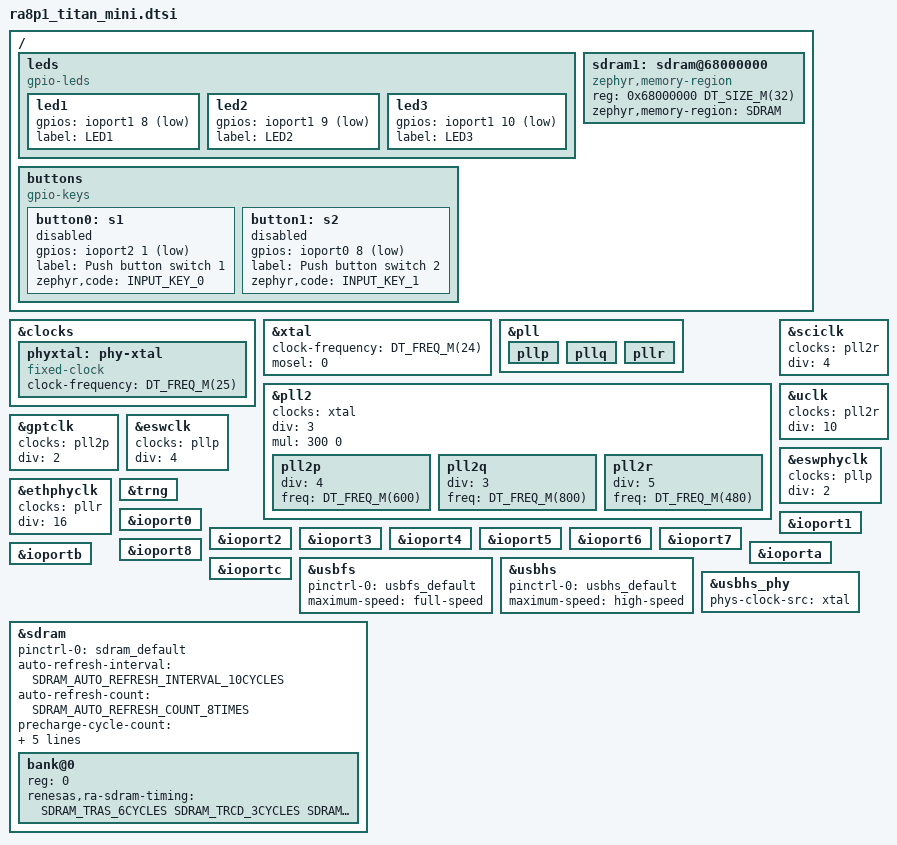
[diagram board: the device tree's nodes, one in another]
/*
 * SPDX-FileCopyrightText: Copyright The Zephyr Project Contributors
 * SPDX-License-Identifier: Apache-2.0
 */

#include <zephyr/dt-bindings/gpio/gpio.h>
#include <zephyr/dt-bindings/input/input-event-codes.h>
#include "ra8p1_titan_mini-pinctrl.dtsi"
#include <zephyr/dt-bindings/memory-attr/memory-attr-arm.h>
#include <zephyr/dt-bindings/memory-controller/renesas,ra-sdram.h>

/ {
	leds {
		compatible = "gpio-leds";

		led1: led1 {
			gpios = <&ioport1 8 GPIO_ACTIVE_LOW>;
			label = "LED1";
		};

		led2: led2 {
			gpios = <&ioport1 9 GPIO_ACTIVE_LOW>;
			label = "LED2";
		};

		led3: led3 {
			gpios = <&ioport1 10 GPIO_ACTIVE_LOW>;
			label = "LED3";
		};
	};

	buttons {
		compatible = "gpio-keys";

		button0: s1 {
			gpios = <&ioport2 1 GPIO_ACTIVE_LOW>;
			label = "Push button switch 1";
			zephyr,code = <INPUT_KEY_0>;
			status = "disabled";
		};

		button1: s2 {
			gpios = <&ioport0 8 (GPIO_PULL_UP | GPIO_ACTIVE_LOW)>;
			label = "Push button switch 2";
			zephyr,code = <INPUT_KEY_1>;
			status = "disabled";
		};
	};

	sdram1: sdram@68000000 {
		compatible = "zephyr,memory-region", "mmio-sram";
		device_type = "memory";
		reg = <0x68000000 DT_SIZE_M(32)>;
		zephyr,memory-region = "SDRAM";
		status = "okay";
	};
};

/* On this board, the PHY chip uses XTAL as clock source,
 * so internal phy clock is not required.
 */
&clocks {
	phyxtal: phy-xtal {
		compatible = "fixed-clock";
		clock-frequency = <DT_FREQ_M(25)>;
		#clock-cells = <0x0>;
		status = "okay";
	};
};

&xtal {
	clock-frequency = <DT_FREQ_M(24)>;
	mosel = <0>;
	#clock-cells = <0>;
	status = "okay";
};

&pll {
	status = "okay";

	pllp: pllp {
		status = "okay";
	};

	pllq: pllq {
		status = "okay";
	};

	pllr: pllr {
		status = "okay";
	};
};

&pll2 {
	clocks = <&xtal>;
	div = <3>;
	mul = <300 0>;
	status = "okay";

	pll2p {
		div = <4>;
		freq = <DT_FREQ_M(600)>;
		status = "okay";
	};

	pll2q {
		div = <3>;
		freq = <DT_FREQ_M(800)>;
		status = "okay";
	};

	pll2r {
		div = <5>;
		freq = <DT_FREQ_M(480)>;
		status = "okay";
	};
};

&sciclk {
	clocks = <&pll2r>;
	div = <4>;
	status = "okay";
};

&uclk {
	clocks = <&pll2r>;
	div = <10>;
	status = "okay";
};

&gptclk {
	clocks = <&pll2p>;
	div = <2>;
	status = "okay";
};

&eswclk {
	clocks = <&pllp>;
	div = <4>;
	status = "okay";
};

&eswphyclk {
	clocks = <&pllp>;
	div = <2>;
	status = "okay";
};

&ethphyclk {
	clocks = <&pllr>;
	div = <16>;
	status = "okay";
};

&trng {
	status = "okay";
};

&ioport0 {
	status = "okay";
};

&ioport1 {
	status = "okay";
};

&ioport2 {
	status = "okay";
};

&ioport3 {
	status = "okay";
};

&ioport4 {
	status = "okay";
};

&ioport5 {
	status = "okay";
};

&ioport6 {
	status = "okay";
};

&ioport7 {
	status = "okay";
};

&ioport8 {
	status = "okay";
};

&ioporta {
	status = "okay";
};

&ioportb {
	status = "okay";
};

&ioportc {
	status = "okay";
};

&usbfs {
	pinctrl-0 = <&usbfs_default>;
	pinctrl-names = "default";
	maximum-speed = "full-speed";
};

&usbhs {
	pinctrl-0 = <&usbhs_default>;
	pinctrl-names = "default";
	maximum-speed = "high-speed";
};

&usbhs_phy {
	phys-clock-src = "xtal";
};

&sdram {
	pinctrl-0 = <&sdram_default>;
	pinctrl-names = "default";
	status = "okay";
	auto-refresh-interval = <SDRAM_AUTO_REFRESH_INTERVAL_10CYCLES>;
	auto-refresh-count = <SDRAM_AUTO_REFRESH_COUNT_8TIMES>;
	precharge-cycle-count = <SDRAM_AUTO_PRECHARGE_CYCLE_3CYCLES>;
	multiplex-addr-shift = "9-bit";
	endian-mode = "little-endian";
	continuous-access;
	bus-width = "16-bit";

	bank@0 {
		reg = <0>;
		renesas,ra-sdram-timing = <SDRAM_TRAS_6CYCLES
					   SDRAM_TRCD_3CYCLES
					   SDRAM_TRP_3CYCLES
					   SDRAM_TWR_2CYCLES
					   SDRAM_TCL_3CYCLES
					   937
					   SDRAM_TREFW_8CYCLES>;
	};
};
